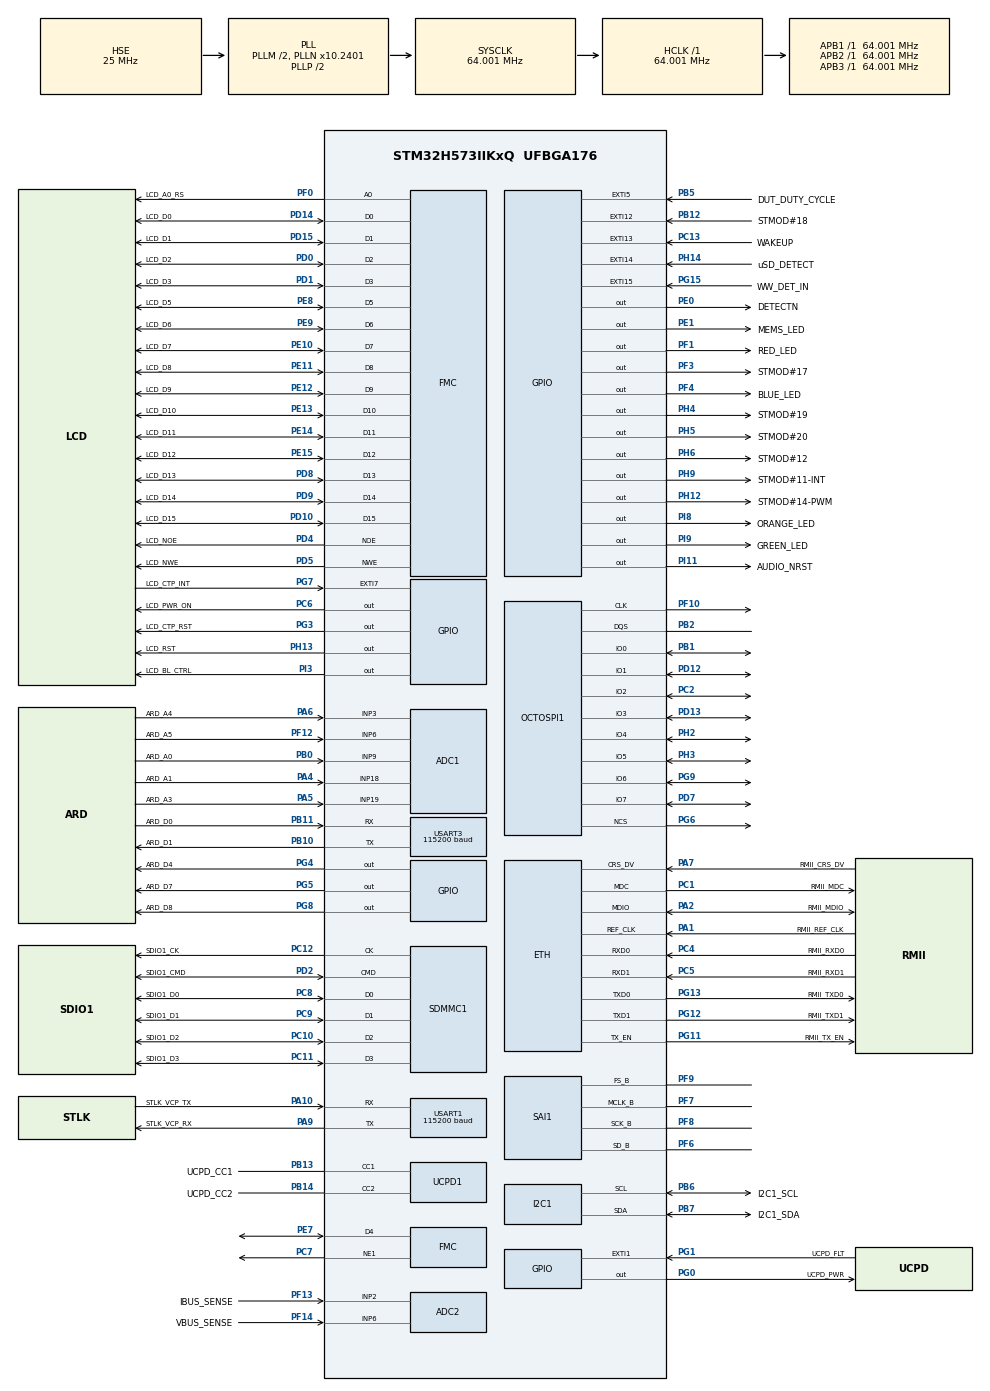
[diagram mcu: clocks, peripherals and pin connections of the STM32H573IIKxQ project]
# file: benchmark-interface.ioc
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ADC1.Channel-0\#ChannelRegularConversion=ADC_CHANNEL_3
ADC1.ClockPrescaler=ADC_CLOCK_ASYNC_DIV2
ADC1.MonitoredBy-0\#ChannelRegularConversion=__NULL
ADC1.NbrOfConversionFlag=1
ADC1.OffsetNumber-0\#ChannelRegularConversion=ADC_OFFSET_NONE
ADC1.Rank-0\#ChannelRegularConversion=1
ADC1.SamplingTime-0\#ChannelRegularConversion=ADC_SAMPLETIME_2CYCLES_5
ADC1.master=1
ADC2.Channel-0\#ChannelRegularConversion=ADC_CHANNEL_2
ADC2.ClockPrescaler=ADC_CLOCK_ASYNC_DIV2
ADC2.MonitoredBy-0\#ChannelRegularConversion=__NULL
ADC2.NbrOfConversionFlag=1
ADC2.OffsetNumber-0\#ChannelRegularConversion=ADC_OFFSET_NONE
ADC2.Rank-0\#ChannelRegularConversion=1
ADC2.SamplingTime-0\#ChannelRegularConversion=ADC_SAMPLETIME_2CYCLES_5
BOOTPATH.BootPathName=LEGACY
BOOTPATH.UserSelectedBootPath=LEGACY
CORTEX_M33_NS.userName=CORTEX_M33
ETH.MediaInterface=HAL_ETH_RMII_MODE
FILEX.FILEX_APPLICATION_THREAD_STACK_SIZE=4 * 1024
FILEX.FX_APP_MEM_POOL_SIZE=6 * 1024
FILEX.FX_DRIVER_SDMMC_INIT=1
FILEX.FX_SD_INTERFACE=1
FILEX.useRTOS=1
GPDMA1.LINKEDLISTMODE_GPDMACH2=DMA_LINKEDLIST_CIRCULAR
GPDMA1.PRIORITY_LL_GPDMACH2=DMA_HIGH_PRIORITY
GPDMA2.LINKEDLISTMODE_GPDMACH2=DMA_LINKEDLIST_CIRCULAR
GPDMA2.PRIORITY_LL_GPDMACH2=DMA_HIGH_PRIORITY
I2C1.Timing=0x108088B1
Linkedlist.MDMA_Channel0.GP_SW.0.BlkHWRequest=DMA_BREQ_SINGLE_BURST
Linkedlist.MDMA_Channel0.GP_SW.0.DataHandling=NONE
Linkedlist.MDMA_Channel0.GP_SW.0.DataSize=0
Linkedlist.MDMA_Channel0.GP_SW.0.DestBurstLength=1
Linkedlist.MDMA_Channel0.GP_SW.0.DestDataWidth=DMA_DEST_DATAWIDTH_HALFWORD
Linkedlist.MDMA_Channel0.GP_SW.0.DestInc=DMA_DINC_FIXED
Linkedlist.MDMA_Channel0.GP_SW.0.Direction=DMA_MEMORY_TO_PERIPH
Linkedlist.MDMA_Channel0.GP_SW.0.DstAddress=0
Linkedlist.MDMA_Channel0.GP_SW.0.Instance=MDMA_Channel0
Linkedlist.MDMA_Channel0.GP_SW.0.LL_MASTERDMA=GPDMA1
Linkedlist.MDMA_Channel0.GP_SW.0.LL_NAME=HeadphoneSAIQueue
Linkedlist.MDMA_Channel0.GP_SW.0.LL_TYPE=LINEAR
Linkedlist.MDMA_Channel0.GP_SW.0.Mode=DMA_NORMAL
Linkedlist.MDMA_Channel0.GP_SW.0.NODE_NAME=NodeTx
Linkedlist.MDMA_Channel0.GP_SW.0.Requestforcodegen=GPDMA1_REQUEST_SAI2_A
Linkedlist.MDMA_Channel0.GP_SW.0.SrcAddress=0
Linkedlist.MDMA_Channel0.GP_SW.0.SrcBurstLength=1
Linkedlist.MDMA_Channel0.GP_SW.0.SrcDataWidth=DMA_SRC_DATAWIDTH_HALFWORD
Linkedlist.MDMA_Channel0.GP_SW.0.SrcInc=DMA_SINC_INCREMENTED
Linkedlist.MDMA_Channel0.GP_SW.0.TransferAllocatedPortSrc=DMA_SRC_ALLOCATED_PORT0
Linkedlist.MDMA_Channel0.GP_SW.0.TransferEventMode=DMA_TCEM_EACH_LL_ITEM_TRANSFER
Linkedlist.MDMA_Channel0.GP_SW.0.TriggerPolarity=DMA_TRIG_POLARITY_MASKED
Linkedlist.MDMA_Channel0.GP_SW.1.BlkHWRequest=DMA_BREQ_SINGLE_BURST
Linkedlist.MDMA_Channel0.GP_SW.1.DataHandling=NONE
Linkedlist.MDMA_Channel0.GP_SW.1.DataSize=0
Linkedlist.MDMA_Channel0.GP_SW.1.DestBurstLength=1
Linkedlist.MDMA_Channel0.GP_SW.1.DestDataWidth=DMA_DEST_DATAWIDTH_HALFWORD
Linkedlist.MDMA_Channel0.GP_SW.1.DestInc=DMA_DINC_FIXED
Linkedlist.MDMA_Channel0.GP_SW.1.Direction=DMA_MEMORY_TO_PERIPH
Linkedlist.MDMA_Channel0.GP_SW.1.DstAddress=0
Linkedlist.MDMA_Channel0.GP_SW.1.Instance=MDMA_Channel0
Linkedlist.MDMA_Channel0.GP_SW.1.LL_MASTERDMA=GPDMA1
Linkedlist.MDMA_Channel0.GP_SW.1.LL_NAME=HeadphoneSAIQueue
Linkedlist.MDMA_Channel0.GP_SW.1.LL_TYPE=LINEAR
Linkedlist.MDMA_Channel0.GP_SW.1.Mode=DMA_NORMAL
Linkedlist.MDMA_Channel0.GP_SW.1.NODE_NAME=NodeTx2
Linkedlist.MDMA_Channel0.GP_SW.1.Requestforcodegen=GPDMA1_REQUEST_SAI2_A
Linkedlist.MDMA_Channel0.GP_SW.1.SrcAddress=0
Linkedlist.MDMA_Channel0.GP_SW.1.SrcBurstLength=1
Linkedlist.MDMA_Channel0.GP_SW.1.SrcDataWidth=DMA_SRC_DATAWIDTH_HALFWORD
Linkedlist.MDMA_Channel0.GP_SW.1.SrcInc=DMA_SINC_INCREMENTED
Linkedlist.MDMA_Channel0.GP_SW.1.TransferAllocatedPortSrc=DMA_SRC_ALLOCATED_PORT0
Linkedlist.MDMA_Channel0.GP_SW.1.TransferEventMode=DMA_TCEM_EACH_LL_ITEM_TRANSFER
Linkedlist.MDMA_Channel0.GP_SW.1.TriggerPolarity=DMA_TRIG_POLARITY_MASKED
Linkedlist.MDMA_Channel0.Request0=GP_SW
Linkedlist.MDMA_Channel0.Request1=GP_SW
Linkedlist.MDMA_Channel0.RequestsNb=2
Linkedlist.MDMA_Channel1.GP_SW.0.BlkHWRequest=DMA_BREQ_SINGLE_BURST
Linkedlist.MDMA_Channel1.GP_SW.0.DataHandling=NONE
Linkedlist.MDMA_Channel1.GP_SW.0.DataSize=0
Linkedlist.MDMA_Channel1.GP_SW.0.DestBurstLength=1
Linkedlist.MDMA_Channel1.GP_SW.0.DestDataWidth=DMA_DEST_DATAWIDTH_HALFWORD
Linkedlist.MDMA_Channel1.GP_SW.0.DestInc=DMA_DINC_FIXED
Linkedlist.MDMA_Channel1.GP_SW.0.Direction=DMA_MEMORY_TO_PERIPH
Linkedlist.MDMA_Channel1.GP_SW.0.DstAddress=0
Linkedlist.MDMA_Channel1.GP_SW.0.Instance=MDMA_Channel1
Linkedlist.MDMA_Channel1.GP_SW.0.LL_MASTERDMA=GPDMA1
Linkedlist.MDMA_Channel1.GP_SW.0.LL_NAME=RawSAIQueue
Linkedlist.MDMA_Channel1.GP_SW.0.LL_TYPE=LINEAR
Linkedlist.MDMA_Channel1.GP_SW.0.Mode=DMA_NORMAL
Linkedlist.MDMA_Channel1.GP_SW.0.NODE_NAME=NodeTx
Linkedlist.MDMA_Channel1.GP_SW.0.Requestforcodegen=GPDMA1_REQUEST_SAI1_B
Linkedlist.MDMA_Channel1.GP_SW.0.SrcAddress=0
Linkedlist.MDMA_Channel1.GP_SW.0.SrcBurstLength=1
Linkedlist.MDMA_Channel1.GP_SW.0.SrcDataWidth=DMA_SRC_DATAWIDTH_HALFWORD
Linkedlist.MDMA_Channel1.GP_SW.0.SrcInc=DMA_SINC_INCREMENTED
Linkedlist.MDMA_Channel1.GP_SW.0.TransferAllocatedPortSrc=DMA_SRC_ALLOCATED_PORT0
Linkedlist.MDMA_Channel1.GP_SW.0.TransferEventMode=DMA_TCEM_BLOCK_TRANSFER
Linkedlist.MDMA_Channel1.GP_SW.0.TriggerPolarity=DMA_TRIG_POLARITY_MASKED
Linkedlist.MDMA_Channel1.Request0=GP_SW
Linkedlist.MDMA_Channel1.RequestsNb=1
Linkedlist.RequestSet0=MDMA_Channel0
Linkedlist.RequestSet1=MDMA_Channel1
Linkedlist.RequestSetsNb=2
Mcu.Family=STM32H5
Mcu.Name=STM32H573IIKxQ
Mcu.Package=UFBGA176
NVIC.EXTI14_IRQn=true\:0\:0\:false\:false\:true\:false\:true\:true\:true
NVIC.EXTI15_IRQn=true\:0\:0\:false\:false\:true\:false\:true\:true\:true
NVIC.EXTI5_IRQn=true\:0\:0\:false\:false\:true\:false\:true\:true\:true
NVIC.GPDMA1_Channel2_IRQn=true\:0\:0\:false\:false\:true\:false\:true\:true\:true
NVIC.GPDMA2_Channel2_IRQn=true\:0\:0\:false\:false\:true\:false\:true\:true\:true
NVIC.PriorityGroup=NVIC_PRIORITYGROUP_4
NVIC.SDMMC1_IRQn=true\:0\:0\:false\:false\:true\:false\:true\:true\:true
NVIC.TIM6_IRQn=true\:0\:0\:false\:false\:true\:false\:false\:true\:true
NVIC.TimeBase=TIM6_IRQn
NVIC.TimeBaseIP=TIM6
NVIC.USART1_IRQn=true\:0\:0\:false\:false\:true\:false\:true\:true\:true
NVIC.USART3_IRQn=true\:0\:0\:false\:false\:true\:false\:true\:true\:true
PA0.GPIO_Label=ARD_A2
PA0.Signal=ADCx_INP0
PA1.GPIO_Label=RMII_REF_CLK
PA1.Mode=RMII
PA1.Signal=ETH_REF_CLK
PA10.GPIO_Label=STLK_VCP_TX
PA10.Mode=Asynchronous
PA10.Signal=USART1_RX
PA11.GPIO_Label=USB_FS_N
PA11.Signal=USB_DM
PA12.GPIO_Label=USB_FS_P
PA12.Signal=USB_DP
PA13(JTMS/SWDIO).GPIO_Label=JTMS
PA13(JTMS/SWDIO).Mode=Trace_Synchro_4bits_JTAG
PA13(JTMS/SWDIO).Signal=DEBUG_JTMS-SWDIO
PA14(JTCK/SWCLK).GPIO_Label=JTCK
PA14(JTCK/SWCLK).Mode=Trace_Synchro_4bits_JTAG
PA14(JTCK/SWCLK).Signal=DEBUG_JTCK-SWCLK
PA15(JTDI).GPIO_Label=JTDI
PA15(JTDI).Mode=Trace_Synchro_4bits_JTAG
PA15(JTDI).Signal=DEBUG_JTDI
PA2.GPIO_Label=RMII_MDIO
PA2.Mode=RMII
PA2.Signal=ETH_MDIO
PA3.GPIO_Label=ARD_D10
PA3.Signal=SPI2_NSS
PA4.GPIO_Label=ARD_A1
PA4.Signal=ADCx_INP18
PA5.GPIO_Label=ARD_A3
PA5.Signal=ADCx_INP19
PA6.GPIO_Label=ARD_A4
PA6.Signal=ADCx_INP3
PA7.GPIO_Label=RMII_CRS_DV
PA7.Mode=RMII
PA7.Signal=ETH_CRS_DV
PA8.GPIO_Label=ARD_D9
PA8.Signal=S_TIM1_CH1
PA9.GPIO_Label=STLK_VCP_RX
PA9.Mode=Asynchronous
PA9.Signal=USART1_TX
PB0.GPIO_Label=ARD_A0
PB0.Signal=ADCx_INP9
PB1.GPIO_Mode=GPIO_MODE_AF_PP
PB1.GPIO_PuPd=GPIO_NOPULL
PB1.GPIO_Speed_High_Default=GPIO_SPEED_FREQ_VERY_HIGH
PB1.Mode=OCTOSPI1_IO_Octo
PB1.Signal=OCTOSPI1_IO0
PB10.GPIO_Label=ARD_D1
PB10.Mode=Asynchronous
PB10.Signal=USART3_TX
PB11.GPIO_Label=ARD_D0
PB11.Mode=Asynchronous
PB11.Signal=USART3_RX
PB12.GPIO_Label=STMOD\#18
PB12.Signal=GPXTI12
PB13.GPIO_Label=UCPD_CC1
PB13.Mode=Source_AllSignals
PB13.Signal=UCPD1_CC1
PB14.GPIO_Label=UCPD_CC2
PB14.Mode=Source_AllSignals
PB14.Signal=UCPD1_CC2
PB15.GPIO_Label=ARD_D11
PB15.Signal=SPI2_MOSI
PB2.Mode=octods_mode
PB2.Signal=OCTOSPI1_DQS
PB3(JTDO/TRACESWO).GPIO_Label=SWO
PB3(JTDO/TRACESWO).Mode=Trace_Synchro_4bits_JTAG
PB3(JTDO/TRACESWO).Signal=DEBUG_JTDO-SWO
PB4(NJTRST).GPIO_Label=NJTRST
PB4(NJTRST).Signal=DEBUG_JTRST
PB5.GPIO_Label=DUT_DUTY_CYCLE
PB5.GPIO_ModeDefaultEXTI=GPIO_MODE_IT_RISING_FALLING
PB5.GPIO_PuPd=GPIO_PULLUP
PB5.Signal=GPXTI5
PB6.GPIO_Label=I2C1_SCL
PB6.Mode=I2C
PB6.Signal=I2C1_SCL
PB7.GPIO_Label=I2C1_SDA
PB7.Mode=I2C
PB7.Signal=I2C1_SDA
PC1.GPIO_Label=RMII_MDC
PC1.Mode=RMII
PC1.Signal=ETH_MDC
PC10.GPIO_Label=SDIO1_D2
PC10.Mode=SD_4_bits_Wide_bus
PC10.Signal=SDMMC1_D2
PC11.GPIO_Label=SDIO1_D3
PC11.Mode=SD_4_bits_Wide_bus
PC11.Signal=SDMMC1_D3
PC12.GPIO_Label=SDIO1_CK
PC12.Mode=SD_4_bits_Wide_bus
PC12.Signal=SDMMC1_CK
PC13.GPIO_Label=WAKEUP
PC13.Signal=GPXTI13
PC14-OSC32_IN(OSC32_IN).Signal=RCC_OSC32_IN
PC15-OSC32_OUT(OSC32_OUT).Signal=RCC_OSC32_OUT
PC2.GPIO_Mode=GPIO_MODE_AF_PP
PC2.GPIO_PuPd=GPIO_NOPULL
PC2.GPIO_Speed_High_Default=GPIO_SPEED_FREQ_VERY_HIGH
PC2.Mode=OCTOSPI1_IO_Octo
PC2.Signal=OCTOSPI1_IO2
PC3.GPIO_Label=PDM_SAI1_SD3
PC3.Signal=SAI1_D3
PC4.GPIO_Label=RMII_RXD0
PC4.Mode=RMII
PC4.Signal=ETH_RXD0
PC5.GPIO_Label=RMII_RXD1
PC5.Mode=RMII
PC5.Signal=ETH_RXD1
PC6.GPIO_Label=LCD_PWR_ON
PC6.Signal=GPIO_Output
PC7.Mode=NorPsramChipSelect1_1
PC7.Signal=FMC_NE1
PC8.GPIO_Label=SDIO1_D0
PC8.Mode=SD_4_bits_Wide_bus
PC8.Signal=SDMMC1_D0
PC9.GPIO_Label=SDIO1_D1
PC9.Mode=SD_4_bits_Wide_bus
PC9.Signal=SDMMC1_D1
PD0.GPIO_Label=LCD_D2
PD0.Signal=FMC_D2_DA2
PD1.GPIO_Label=LCD_D3
PD1.Signal=FMC_D3_DA3
PD10.GPIO_Label=LCD_D15
PD10.Signal=FMC_D15_DA15
PD11.Signal=SAI1_CK1
PD12.GPIO_Mode=GPIO_MODE_AF_PP
PD12.GPIO_PuPd=GPIO_NOPULL
PD12.GPIO_Speed_High_Default=GPIO_SPEED_FREQ_VERY_HIGH
PD12.Mode=OCTOSPI1_IO_Octo
PD12.Signal=OCTOSPI1_IO1
PD13.GPIO_Mode=GPIO_MODE_AF_PP
PD13.GPIO_PuPd=GPIO_NOPULL
PD13.GPIO_Speed_High_Default=GPIO_SPEED_FREQ_VERY_HIGH
PD13.Mode=OCTOSPI1_IO_Octo
PD13.Signal=OCTOSPI1_IO3
PD14.GPIO_Label=LCD_D0
PD14.Signal=FMC_D0_DA0
PD15.GPIO_Label=LCD_D1
PD15.Signal=FMC_D1_DA1
PD2.GPIO_Label=SDIO1_CMD
PD2.Mode=SD_4_bits_Wide_bus
PD2.Signal=SDMMC1_CMD
PD3.GPIO_Label=LCD_TE
PD3.Signal=FMC_CLK
PD4.GPIO_Label=LCD_NOE
PD4.Signal=FMC_NOE
PD5.GPIO_Label=LCD_NWE
PD5.Signal=FMC_NWE
PD6.Signal=SAI1_SD_A
PD7.Mode=OCTOSPI1_IO_Octo
PD7.Signal=OCTOSPI1_IO7
PD8.GPIO_Label=LCD_D13
PD8.Signal=FMC_D13_DA13
PD9.GPIO_Label=LCD_D14
PD9.Signal=FMC_D14_DA14
PE0.GPIO_Label=DETECTN
PE0.Signal=GPIO_Output
PE1.GPIO_Label=MEMS_LED
PE1.Signal=GPIO_Output
PE10.GPIO_Label=LCD_D7
PE10.Signal=FMC_D7_DA7
PE11.GPIO_Label=LCD_D8
PE11.Signal=FMC_D8_DA8
PE12.GPIO_Label=LCD_D9
PE12.Signal=FMC_D9_DA9
PE13.GPIO_Label=LCD_D10
PE13.Signal=FMC_D10_DA10
PE14.GPIO_Label=LCD_D11
PE14.Signal=FMC_D11_DA11
PE15.GPIO_Label=LCD_D12
PE15.Signal=FMC_D12_DA12
PE2.Mode=Trace_Synchro_4bits_JTAG
PE2.Signal=DEBUG_TRACECLK
PE3.GPIO_Label=TRACED0
PE3.Mode=Trace_Synchro_4bits_JTAG
PE3.Signal=DEBUG_TRACED0
PE4.Signal=SAI1_D2
PE5.GPIO_Label=TRACED2
PE5.Mode=Trace_Synchro_4bits_JTAG
PE5.Signal=DEBUG_TRACED2
PE6.GPIO_Label=TRACED3
PE6.Mode=Trace_Synchro_4bits_JTAG
PE6.Signal=DEBUG_TRACED3
PE7.Signal=FMC_D4_DA4
PE8.GPIO_Label=LCD_D5
PE8.Signal=FMC_D5_DA5
PE9.GPIO_Label=LCD_D6
PE9.Signal=FMC_D6_DA6
PF0.GPIO_Label=LCD_A0_RS
PF0.Signal=FMC_A0
PF1.GPIO_Label=RED_LED
PF1.PinState=GPIO_PIN_SET
PF1.Signal=GPIO_Output
PF10.GPIO_Mode=GPIO_MODE_AF_PP
PF10.GPIO_PuPd=GPIO_NOPULL
PF10.GPIO_Speed_High_Default=GPIO_SPEED_FREQ_VERY_HIGH
PF10.Mode=octods_mode
PF10.Signal=OCTOSPI1_CLK
PF11.GPIO_Label=STMOD\#13
PF11.Signal=ADC1_INP2
PF12.GPIO_Label=ARD_A5
PF12.Mode=IN6-Single-Ended
PF12.Signal=ADC1_INP6
PF13.GPIO_Label=IBUS_SENSE
PF13.Mode=IN2-Single-Ended
PF13.Signal=ADC2_INP2
PF14.GPIO_Label=VBUS_SENSE
PF14.Mode=IN6-Single-Ended
PF14.Signal=ADC2_INP6
PF3.GPIO_Label=STMOD\#17
PF3.Signal=GPIO_Output
PF4.GPIO_Label=BLUE_LED
PF4.PinState=GPIO_PIN_SET
PF4.Signal=GPIO_Output
PF6.Mode=SAI_B_MasterWithClock
PF6.Signal=SAI1_SD_B
PF7.Mode=SAI_B_MasterWithClock
PF7.Signal=SAI1_MCLK_B
PF8.Mode=SAI_B_MasterWithClock
PF8.Signal=SAI1_SCK_B
PF9.Mode=SAI_B_MasterWithClock
PF9.Signal=SAI1_FS_B
PG0.GPIO_Label=UCPD_PWR
PG0.Signal=GPIO_Output
PG1.GPIO_Label=UCPD_FLT
PG1.Signal=GPXTI1
PG10.GPIO_Label=SAI2_SD_B
PG10.Signal=SAI2_SD_B
PG11.GPIO_Label=RMII_TX_EN
PG11.Mode=RMII
PG11.Signal=ETH_TX_EN
PG12.GPIO_Label=RMII_TXD1
PG12.Mode=RMII
PG12.Signal=ETH_TXD1
PG13.GPIO_Label=RMII_TXD0
PG13.Mode=RMII
PG13.Signal=ETH_TXD0
PG14.GPIO_Label=TRACED1
PG14.Mode=Trace_Synchro_4bits_JTAG
PG14.Signal=DEBUG_TRACED1
PG15.GPIO_Label=WW_DET_IN
PG15.GPIO_ModeDefaultEXTI=GPIO_MODE_IT_FALLING
PG15.GPIO_PuPd=GPIO_PULLUP
PG15.Signal=GPXTI15
PG3.GPIO_Label=LCD_CTP_RST
PG3.Signal=GPIO_Output
PG4.GPIO_Label=ARD_D4
PG4.Signal=GPIO_Output
PG5.GPIO_Label=ARD_D7
PG5.Signal=GPIO_Output
PG6.GPIO_Mode=GPIO_MODE_AF_PP
PG6.GPIO_PuPd=GPIO_NOPULL
PG6.GPIO_Speed_High_Default=GPIO_SPEED_FREQ_VERY_HIGH
PG6.Mode=octods_mode
PG6.Signal=OCTOSPI1_NCS
PG7.GPIO_Label=LCD_CTP_INT
PG7.Signal=GPXTI7
PG8.GPIO_Label=ARD_D8
PG8.Signal=GPIO_Output
PG9.Mode=OCTOSPI1_IO_Octo
PG9.Signal=OCTOSPI1_IO6
PH0-OSC_IN(PH0).Mode=HSE-DIG-External-Clock-Source
PH0-OSC_IN(PH0).Signal=RCC_OSC_IN
PH10.GPIO_Label=ARD_D6
PH10.Signal=S_TIM5_CH1
PH11.GPIO_Label=ARD_D5
PH11.Signal=S_TIM5_CH2
PH12.GPIO_Label=STMOD\#14-PWM
PH12.Signal=GPIO_Output
PH13.GPIO_Label=LCD_RST
PH13.Signal=GPIO_Output
PH14.GPIO_Label=uSD_DETECT
PH14.GPIO_ModeDefaultEXTI=GPIO_MODE_IT_RISING_FALLING
PH14.GPIO_PuPd=GPIO_PULLUP
PH14.Signal=GPXTI14
PH2.Mode=OCTOSPI1_IO_Octo
PH2.Signal=OCTOSPI1_IO4
PH3.Mode=OCTOSPI1_IO_Octo
PH3.Signal=OCTOSPI1_IO5
PH4.GPIO_Label=STMOD\#19
PH4.Signal=GPIO_Output
PH5.GPIO_Label=STMOD\#20
PH5.Signal=GPIO_Output
PH6.GPIO_Label=STMOD\#12
PH6.Signal=GPIO_Output
PH7.GPIO_Label=STMOD\#12-RST
PH7.Signal=SPI5_MISO
PH8.GPIO_Label=STMOD\#9-MISOs
PH8.Signal=SPI5_MOSI
PH9.GPIO_Label=STMOD\#11-INT
PH9.Signal=GPIO_Output
PI1.GPIO_Label=ARD_D13
PI1.Signal=SPI2_SCK
PI10.GPIO_Label=RMII_RX_ER
PI10.Signal=ETH_RX_ER
PI11.GPIO_Label=AUDIO_NRST
PI11.PinState=GPIO_PIN_SET
PI11.Signal=GPIO_Output
PI2.GPIO_Label=ARD_D12
PI2.Signal=SPI2_MISO
PI3.GPIO_Label=LCD_BL_CTRL
PI3.Signal=GPIO_Output
PI4.GPIO_Label=SAI2_MCLK_A
PI4.Signal=SAI2_MCLK_A
PI5.GPIO_Label=SAI2_SCK_A
PI5.Signal=SAI2_SCK_A
PI6.GPIO_Label=SAI2_SD_A
PI6.Signal=SAI2_SD_A
PI7.GPIO_Label=SAI2_FS_A
PI7.Signal=SAI2_FS_A
PI8.GPIO_Label=ORANGE_LED
PI8.PinState=GPIO_PIN_SET
PI8.Signal=GPIO_Output
PI9.GPIO_Label=GREEN_LED
PI9.PinState=GPIO_PIN_SET
PI9.Signal=GPIO_Output
ProjectManager.HeapSize=0x200
ProjectManager.StackSize=0x400
ProjectManager.TargetToolchain=STM32CubeIDE
RCC.ADCFreq_Value=64000701.904296875
RCC.AHBFreq_Value=64000701.904296875
RCC.APB1Freq_Value=64000701.904296875
RCC.APB1TimFreq_Value=64000701.904296875
RCC.APB2Freq_Value=64000701.904296875
RCC.APB2TimFreq_Value=64000701.904296875
RCC.APB3Freq_Value=64000701.904296875
RCC.CSI_VALUE=4000000
RCC.CortexFreq_Value=64000701.904296875
RCC.EPOD_VALUE=25000000
RCC.HCLKFreq_Value=64000701.904296875
RCC.HSE_VALUE=25000000
RCC.HSI48_VALUE=48000000
RCC.HSIDiv=RCC_HSI_DIV1
RCC.HSI_VALUE=64000000
RCC.LSE_VALUE=32768
RCC.LSIRC_VALUE=32000
RCC.PLL2FRACN=0
RCC.PLL2M=25
RCC.PLL2N=96
RCC.PLL2P=5
RCC.PLL2Source=RCC_PLL2_SOURCE_HSI
RCC.PLL3FRACN=0
RCC.PLLFRACN=1967
RCC.PLLM=2
RCC.PLLN=10
RCC.PLLSourceVirtual=RCC_PLL1_SOURCE_HSE
RCC.SYSCLKFreq_VALUE=64000701.904296875
RCC.SYSCLKSource=RCC_SYSCLKSOURCE_PLLCLK
RCC.USBFreq_Value=48000000
RCC.VCOOutputFreq_Value=128001403.80859375
SAI1.AudioFrequency-SAI_B_MasterWithClock=SAI_AUDIO_FREQUENCY_16K
SAI1.ErrorAudioFreq-SAI_B_MasterWithClock=0.0 %
SAI1.InitProtocol-SAI_B_MasterWithClock=Enable
SAI1.Instance-SAI_B_MasterWithClock=SAI$Index_Block_B
SAI1.MckOutput-SAI_B_MasterWithClock=SAI_MCK_OUTPUT_ENABLE
SAI1.NoDivider-SAI_B_MasterWithClock=SAI_MASTERDIVIDER_ENABLE
SAI1.RealAudioFreq-SAI_B_MasterWithClock=16.0 KHz
SAI1.VirtualMode-SAI_B_MasterWithClock=VM_MASTER
SAI1.VirtualProtocol-SAI_B_BASIC=VM_BASIC_PROTOCOL
SDMMC1.ClockDiv=4
SH.ADCx_INP0.0=ADC1_INP0
SH.ADCx_INP18.0=ADC1_INP18,IN18-Single-Ended
SH.ADCx_INP19.0=ADC1_INP19,IN19-Single-Ended
SH.ADCx_INP3.0=ADC1_INP3,IN3-Single-Ended
SH.ADCx_INP9.0=ADC1_INP9,IN9-Single-Ended
SH.FMC_A0.0=FMC_A0,1b-a1
SH.FMC_CLK.0=FMC_CLK
SH.FMC_D0_DA0.0=FMC_D0,16b-d1
SH.FMC_D10_DA10.0=FMC_D10,16b-d1
SH.FMC_D11_DA11.0=FMC_D11,16b-d1
SH.FMC_D12_DA12.0=FMC_D12,16b-d1
SH.FMC_D13_DA13.0=FMC_D13,16b-d1
SH.FMC_D14_DA14.0=FMC_D14,16b-d1
SH.FMC_D15_DA15.0=FMC_D15,16b-d1
SH.FMC_D1_DA1.0=FMC_D1,16b-d1
SH.FMC_D2_DA2.0=FMC_D2,16b-d1
SH.FMC_D3_DA3.0=FMC_D3,16b-d1
SH.FMC_D4_DA4.0=FMC_D4,16b-d1
SH.FMC_D5_DA5.0=FMC_D5,16b-d1
SH.FMC_D6_DA6.0=FMC_D6,16b-d1
SH.FMC_D7_DA7.0=FMC_D7,16b-d1
SH.FMC_D8_DA8.0=FMC_D8,16b-d1
SH.FMC_D9_DA9.0=FMC_D9,16b-d1
SH.FMC_NOE.0=FMC_NOE,Sram1
SH.FMC_NWE.0=FMC_NWE,Sram1
SH.S_TIM1_CH1.0=TIM1_CH1
SH.S_TIM5_CH1.0=TIM5_CH1
SH.S_TIM5_CH2.0=TIM5_CH2
THREADX.AZRTOS_APP_MEM_ALLOCATION_METHOD=1
THREADX.TX_APP_CREATION=1
THREADX.TX_APP_GENERATE_INIT_CODE=true
THREADX.TX_APP_MEM_POOL_SIZE=2 * 1024
THREADX.TX_APP_STACK_SIZE=1024
TIM2.Prescaler=640-1
USART1.BaudRate=115200
USART1.FIFOMode=FIFOMODE_ENABLE
USART1.VirtualMode=VM_ASYNC
USART3.BaudRate=115200
USART3.FIFOMode=FIFOMODE_ENABLE
USART3.VirtualMode=VM_ASYNC
VP_BOOTPATH_VS_BOOTPATH.Mode=BP_Activate
VP_FILEX_VS_FileOoSystemJjFileXJjCore.Mode=FileX_Core
VP_FILEX_VS_SDOointerface.Mode=SD_interface
VP_GPDMA1_VS_GPDMACH2.Mode=LINKEDLIST_GPDMACH2
VP_GPDMA2_VS_GPDMACH2.Mode=LINKEDLIST_GPDMACH2
VP_ICACHE_VS_ICACHE.Mode=DefaultMode
VP_MEMORYMAP_VS_MEMORYMAP.Mode=CurAppReg
VP_PWR_VS_DBSignals.Mode=DisableDeadBatterySignals
VP_PWR_VS_LPOM.Mode=PowerOptimisation
VP_PWR_VS_SECSignals.Mode=Security/Privilege
VP_SAI1_VP_$IpInstance_SAIB_SAI_BASIC.Mode=SAI_B_BASIC
VP_SYS_VS_tim6.Mode=TIM6
VP_THREADX_VS_RTOSJjThreadXJjCoreJjDefault.Mode=Core_Default
VP_TIM2_VS_ClockSourceINT.Mode=Internal
board=STM32H573I-DK

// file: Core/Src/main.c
/* USER CODE BEGIN Header */
/**
  ******************************************************************************
  * @file           : main.c
  * @brief          : Main program body
  ******************************************************************************
  * @attention
  *
  * Copyright (c) 2023 STMicroelectronics.
  * All rights reserved.
  *
  * This software is licensed under terms that can be found in the LICENSE file
  * in the root directory of this software component.
  * If no LICENSE file comes with this software, it is provided AS-IS.
  *
  ******************************************************************************
  */
/* USER CODE END Header */
#include "app_threadx.h"
#include "main.h"
#include "adc.h"
#include "eth.h"
#include "gpdma.h"
#include "i2c.h"
#include "icache.h"
#include "memorymap.h"
#include "octospi.h"
#include "sai.h"
#include "sdmmc.h"
#include "tim.h"
#include "ucpd.h"
#include "usart.h"
#include "gpio.h"
#include "fmc.h"

/* USER CODE BEGIN Includes */

#include"audio.h"

/* USER CODE END Includes */

void SystemClock_Config(void);

int main(void)
{

  /* MCU Configuration--------------------------------------------------------*/

  /* Reset of all peripherals, Initializes the Flash interface and the Systick. */
  HAL_Init();

  /* Configure the system clock */
  SystemClock_Config();

  /* Initialize all configured peripherals */
  MX_GPIO_Init();
  MX_GPDMA1_Init();
  MX_GPDMA2_Init();
  MX_ETH_Init();
  MX_FMC_Init();
  MX_ICACHE_Init();
  MX_OCTOSPI1_Init();
  MX_SDMMC1_SD_Init();
  MX_UCPD1_Init();
  MX_USART1_UART_Init();
  MX_USART3_UART_Init();
  MX_ADC1_Init();
  MX_ADC2_Init();
  MX_SAI1_Init();
  MX_I2C1_Init();
  MX_TIM2_Init();
  /* USER CODE BEGIN 2 */
  HAL_TIM_Base_Start(&htim2); // start timer

  /* USER CODE END 2 */

  MX_ThreadX_Init();

  /* We should never get here as control is now taken by the scheduler */
  /* Infinite loop */
  while (1)
  {

  }
}

void SystemClock_Config(void)
{
  RCC_OscInitTypeDef RCC_OscInitStruct = {0};
  RCC_ClkInitTypeDef RCC_ClkInitStruct = {0};

  /** Configure the main internal regulator output voltage
  */
  __HAL_PWR_VOLTAGESCALING_CONFIG(PWR_REGULATOR_VOLTAGE_SCALE3);

  while(!__HAL_PWR_GET_FLAG(PWR_FLAG_VOSRDY)) {}

  /** Initializes the RCC Oscillators according to the specified parameters
  * in the RCC_OscInitTypeDef structure.
  */
  RCC_OscInitStruct.OscillatorType = RCC_OSCILLATORTYPE_HSI|RCC_OSCILLATORTYPE_HSE;
  RCC_OscInitStruct.HSEState = RCC_HSE_BYPASS_DIGITAL;
  RCC_OscInitStruct.HSIState = RCC_HSI_ON;
  RCC_OscInitStruct.HSIDiv = RCC_HSI_DIV1;
  RCC_OscInitStruct.HSICalibrationValue = RCC_HSICALIBRATION_DEFAULT;
  RCC_OscInitStruct.PLL.PLLState = RCC_PLL_ON;
  RCC_OscInitStruct.PLL.PLLSource = RCC_PLL1_SOURCE_HSE;
  RCC_OscInitStruct.PLL.PLLM = 2;
  RCC_OscInitStruct.PLL.PLLN = 10;
  RCC_OscInitStruct.PLL.PLLP = 2;
  RCC_OscInitStruct.PLL.PLLQ = 2;
  RCC_OscInitStruct.PLL.PLLR = 2;
  RCC_OscInitStruct.PLL.PLLRGE = RCC_PLL1_VCIRANGE_3;
  RCC_OscInitStruct.PLL.PLLVCOSEL = RCC_PLL1_VCORANGE_WIDE;
  RCC_OscInitStruct.PLL.PLLFRACN = 1967;
  if (HAL_RCC_OscConfig(&RCC_OscInitStruct) != HAL_OK)
  {
    Error_Handler();
  }

  /** Initializes the CPU, AHB and APB buses clocks
  */
  RCC_ClkInitStruct.ClockType = RCC_CLOCKTYPE_HCLK|RCC_CLOCKTYPE_SYSCLK
                              |RCC_CLOCKTYPE_PCLK1|RCC_CLOCKTYPE_PCLK2
                              |RCC_CLOCKTYPE_PCLK3;
  RCC_ClkInitStruct.SYSCLKSource = RCC_SYSCLKSOURCE_PLLCLK;
  RCC_ClkInitStruct.AHBCLKDivider = RCC_SYSCLK_DIV1;
  RCC_ClkInitStruct.APB1CLKDivider = RCC_HCLK_DIV1;
  RCC_ClkInitStruct.APB2CLKDivider = RCC_HCLK_DIV1;
  RCC_ClkInitStruct.APB3CLKDivider = RCC_HCLK_DIV1;

  if (HAL_RCC_ClockConfig(&RCC_ClkInitStruct, FLASH_LATENCY_3) != HAL_OK)
  {
    Error_Handler();
  }
}

/* USER CODE BEGIN 4 */
int __io_putchar(int ch)
{
 // Write character to ITM ch.0
 ITM_SendChar(ch);
 return(ch);
}
/* USER CODE END 4 */

void HAL_TIM_PeriodElapsedCallback(TIM_HandleTypeDef *htim)
{
  if (htim->Instance == TIM6) {
    HAL_IncTick();
  }
}

void Error_Handler(void)
{
  __disable_irq();
  while (1)
  {
  }
}
